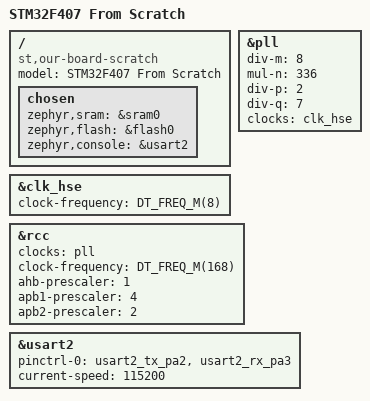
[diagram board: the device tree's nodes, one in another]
/* SPDX-License-Identifier: Apache-2.0 */

/dts-v1/;

#include <st/f4/stm32f407Xg.dtsi>
#include <st/f4/stm32f407v(e-g)tx-pinctrl.dtsi>

/ {
	model = "STM32F407 From Scratch";
	compatible = "st,our-board-scratch";

	chosen {
		zephyr,sram = &sram0;
		zephyr,flash = &flash0;
		zephyr,console = &usart2;
	};
};

&clk_hse {
	clock-frequency = <DT_FREQ_M(8)>;
	status = "okay";
};

&pll {
	div-m = <8>;
	mul-n = <336>;
	div-p = <2>;
	div-q = <7>;
	clocks = <&clk_hse>;
	status = "okay";
};

&rcc {
	clocks = <&pll>;
	clock-frequency = <DT_FREQ_M(168)>;
	ahb-prescaler = <1>;
	apb1-prescaler = <4>;
	apb2-prescaler = <2>;
};

&usart2 {
	pinctrl-0 = <&usart2_tx_pa2 &usart2_rx_pa3>;
	pinctrl-names = "default";
	current-speed = <115200>;
	status = "okay";
};
